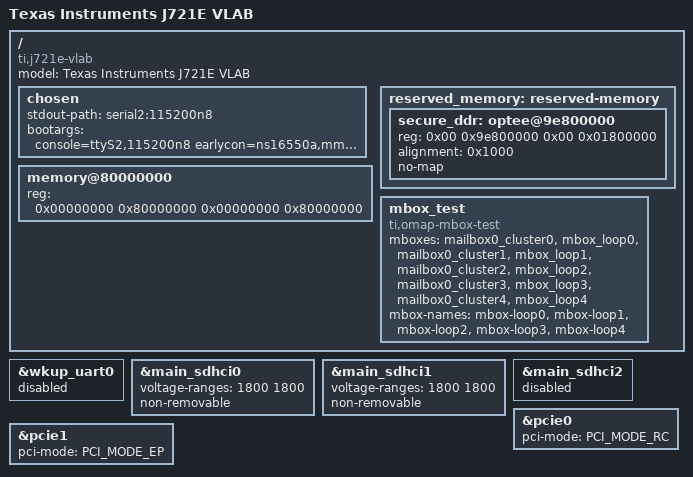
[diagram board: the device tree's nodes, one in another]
// SPDX-License-Identifier: GPL-2.0
/*
 * Copyright (C) 2016-2019 Texas Instruments Incorporated - http://www.ti.com/
 */

/dts-v1/;

#include "k3-j721e.dtsi"
#include <dt-bindings/pci/pci.h>

/ {
	compatible =  "ti,j721e-vlab", "ti,j721e";
	model = "Texas Instruments J721E VLAB";

	chosen {
		stdout-path = "serial2:115200n8";
		bootargs = "console=ttyS2,115200n8 earlycon=ns16550a,mmio32,0x02800000";
	};

	memory@80000000 {
		device_type = "memory";
		/* 2G RAM */
		reg = <0x00000000 0x80000000 0x00000000 0x80000000>;

	};

	reserved_memory: reserved-memory {
		#address-cells = <2>;
		#size-cells = <2>;
		ranges;

		secure_ddr: optee@9e800000 {
			reg = <0x00 0x9e800000 0x00 0x01800000>;
			alignment = <0x1000>;
			no-map;
		};
	};

	mbox_test {
		compatible = "ti,omap-mbox-test";
		mboxes = <&mailbox0_cluster0 &mbox_loop0>,
			 <&mailbox0_cluster1 &mbox_loop1>,
			 <&mailbox0_cluster2 &mbox_loop2>,
			 <&mailbox0_cluster3 &mbox_loop3>,
			 <&mailbox0_cluster4 &mbox_loop4>;
		mbox-names = "mbox-loop0", "mbox-loop1", "mbox-loop2",
			     "mbox-loop3", "mbox-loop4";
	};
};

&wkup_uart0 {
	/* Wakeup UART is used by System firmware */
	status = "disabled";
};

&main_sdhci0 {
	/* eMMC */
	voltage-ranges = <1800 1800>;
	non-removable;
};

&main_sdhci1 {
	/* eMMC */
	voltage-ranges = <1800 1800>;
	non-removable;
};

&main_sdhci2 {
	/* Unused */
	status = "disabled";
};

&pcie0 {
	pci-mode = <PCI_MODE_RC>;
	status = "okay";
};

&pcie1 {
	pci-mode = <PCI_MODE_EP>;
	status = "okay";
};

#include "k3-dss-640x480-port0-dpi.dtsi"
#include "k3-dss-640x480-port1-dpi.dtsi"
